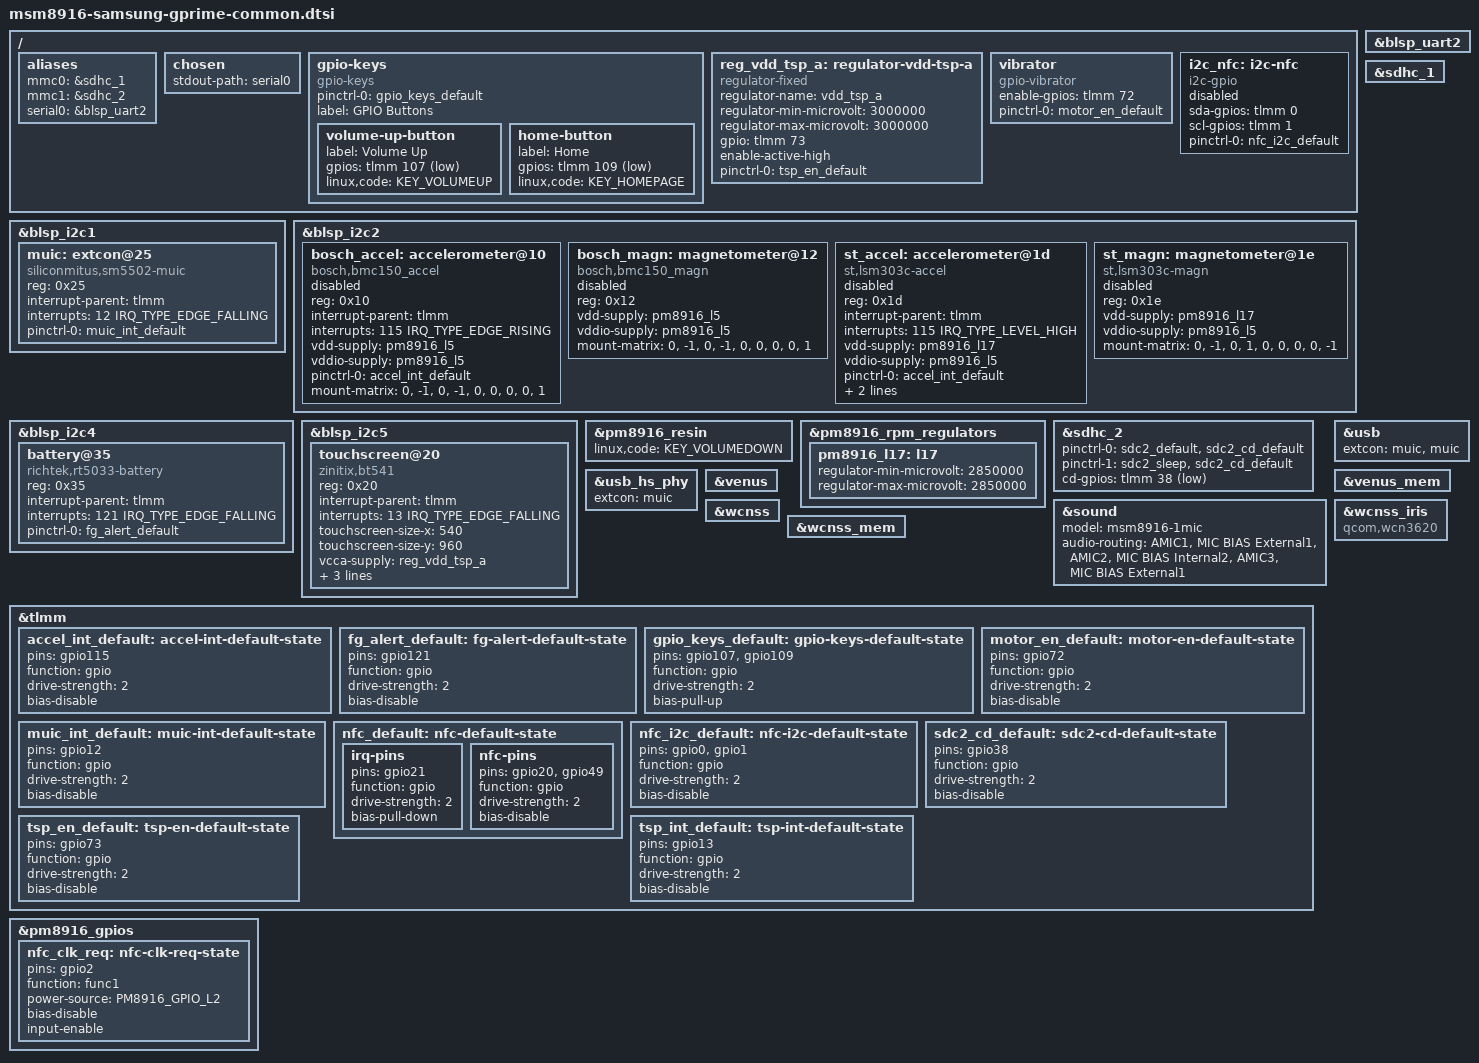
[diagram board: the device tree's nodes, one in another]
// SPDX-License-Identifier: GPL-2.0-only

#include "msm8916-pm8916.dtsi"
#include "msm8916-modem-qdsp6.dtsi"

#include <dt-bindings/gpio/gpio.h>
#include <dt-bindings/input/input.h>
#include <dt-bindings/interrupt-controller/irq.h>
#include <dt-bindings/pinctrl/qcom,pmic-gpio.h>

/ {
	aliases {
		mmc0 = &sdhc_1; /* eMMC */
		mmc1 = &sdhc_2; /* SD card */
		serial0 = &blsp_uart2;
	};

	chosen {
		stdout-path = "serial0";
	};

	gpio-keys {
		compatible = "gpio-keys";

		pinctrl-0 = <&gpio_keys_default>;
		pinctrl-names = "default";

		label = "GPIO Buttons";

		volume-up-button {
			label = "Volume Up";
			gpios = <&tlmm 107 GPIO_ACTIVE_LOW>;
			linux,code = <KEY_VOLUMEUP>;
		};

		home-button {
			label = "Home";
			gpios = <&tlmm 109 GPIO_ACTIVE_LOW>;
			linux,code = <KEY_HOMEPAGE>;
		};
	};

	reg_vdd_tsp_a: regulator-vdd-tsp-a {
		compatible = "regulator-fixed";
		regulator-name = "vdd_tsp_a";
		regulator-min-microvolt = <3000000>;
		regulator-max-microvolt = <3000000>;

		gpio = <&tlmm 73 GPIO_ACTIVE_HIGH>;
		enable-active-high;

		pinctrl-0 = <&tsp_en_default>;
		pinctrl-names = "default";
	};

	vibrator {
		compatible = "gpio-vibrator";
		enable-gpios = <&tlmm 72 GPIO_ACTIVE_HIGH>;

		pinctrl-0 = <&motor_en_default>;
		pinctrl-names = "default";
	};

	i2c_nfc: i2c-nfc {
		compatible = "i2c-gpio";
		sda-gpios = <&tlmm 0 (GPIO_ACTIVE_HIGH|GPIO_OPEN_DRAIN)>;
		scl-gpios = <&tlmm 1 (GPIO_ACTIVE_HIGH|GPIO_OPEN_DRAIN)>;

		pinctrl-0 = <&nfc_i2c_default>;
		pinctrl-names = "default";

		#address-cells = <1>;
		#size-cells = <0>;

		/* Used for NFC on some variants */
		status = "disabled";
	};
};

&blsp_i2c1 {
	status = "okay";

	muic: extcon@25 {
		compatible = "siliconmitus,sm5502-muic";
		reg = <0x25>;
		interrupt-parent = <&tlmm>;
		interrupts = <12 IRQ_TYPE_EDGE_FALLING>;
		pinctrl-0 = <&muic_int_default>;
		pinctrl-names = "default";
	};
};

&blsp_i2c2 {
	/* Available sensors vary depending on model variant */
	status = "okay";

	bosch_accel: accelerometer@10 {
		compatible = "bosch,bmc150_accel";
		reg = <0x10>;
		interrupt-parent = <&tlmm>;
		interrupts = <115 IRQ_TYPE_EDGE_RISING>;

		vdd-supply = <&pm8916_l5>;
		vddio-supply = <&pm8916_l5>;

		pinctrl-0 = <&accel_int_default>;
		pinctrl-names = "default";

		mount-matrix = "0", "-1", "0",
			      "-1",  "0", "0",
			       "0",  "0", "1";

		status = "disabled";
	};

	bosch_magn: magnetometer@12 {
		compatible = "bosch,bmc150_magn";
		reg = <0x12>;

		vdd-supply = <&pm8916_l5>;
		vddio-supply = <&pm8916_l5>;

		mount-matrix = "0", "-1", "0",
			      "-1",  "0", "0",
			       "0",  "0", "1";

		status = "disabled";
	};

	st_accel: accelerometer@1d {
		compatible = "st,lsm303c-accel";
		reg = <0x1d>;
		interrupt-parent = <&tlmm>;
		interrupts = <115 IRQ_TYPE_LEVEL_HIGH>;
		interrupt-names = "INT1";

		vdd-supply = <&pm8916_l17>;
		vddio-supply = <&pm8916_l5>;

		pinctrl-0 = <&accel_int_default>;
		pinctrl-names = "default";

		st,drdy-int-pin = <1>;
		mount-matrix = "0", "-1",  "0",
			       "1",  "0",  "0",
			       "0",  "0", "-1";

		status = "disabled";
	};

	st_magn: magnetometer@1e {
		compatible = "st,lsm303c-magn";
		reg = <0x1e>;

		vdd-supply = <&pm8916_l17>;
		vddio-supply = <&pm8916_l5>;

		mount-matrix = "0", "-1",  "0",
			       "1",  "0",  "0",
			       "0",  "0", "-1";

		status = "disabled";
	};
};

&blsp_i2c4 {
	status = "okay";

	battery@35 {
		compatible = "richtek,rt5033-battery";
		reg = <0x35>;

		interrupt-parent = <&tlmm>;
		interrupts = <121 IRQ_TYPE_EDGE_FALLING>;

		pinctrl-0 = <&fg_alert_default>;
		pinctrl-names = "default";
	};
};

&blsp_i2c5 {
	status = "okay";

	touchscreen@20 {
		compatible = "zinitix,bt541";
		reg = <0x20>;

		interrupt-parent = <&tlmm>;
		interrupts = <13 IRQ_TYPE_EDGE_FALLING>;

		touchscreen-size-x = <540>;
		touchscreen-size-y = <960>;

		vcca-supply = <&reg_vdd_tsp_a>;
		vdd-supply = <&pm8916_l6>;

		pinctrl-0 = <&tsp_int_default>;
		pinctrl-names = "default";

		linux,keycodes = <KEY_APPSELECT KEY_BACK>;
	};
};

&blsp_uart2 {
	status = "okay";
};

&pm8916_resin {
	linux,code = <KEY_VOLUMEDOWN>;
	status = "okay";
};

&pm8916_rpm_regulators {
	pm8916_l17: l17 {
		regulator-min-microvolt = <2850000>;
		regulator-max-microvolt = <2850000>;
	};
};

&sdhc_1 {
	status = "okay";
};

&sdhc_2 {
	pinctrl-0 = <&sdc2_default &sdc2_cd_default>;
	pinctrl-1 = <&sdc2_sleep &sdc2_cd_default>;
	pinctrl-names = "default", "sleep";

	cd-gpios = <&tlmm 38 GPIO_ACTIVE_LOW>;

	status = "okay";
};

&sound {
	model = "msm8916-1mic";
	audio-routing =
		"AMIC1", "MIC BIAS External1",
		"AMIC2", "MIC BIAS Internal2",
		"AMIC3", "MIC BIAS External1";
};

&usb {
	extcon = <&muic>, <&muic>;
	status = "okay";
};

&usb_hs_phy {
	extcon = <&muic>;
};

&venus {
	status = "okay";
};

&venus_mem {
	status = "okay";
};

&wcnss {
	status = "okay";
};

&wcnss_iris {
	compatible = "qcom,wcn3620";
};

&wcnss_mem {
	status = "okay";
};

&tlmm {
	accel_int_default: accel-int-default-state {
		pins = "gpio115";
		function = "gpio";
		drive-strength = <2>;
		bias-disable;
	};

	fg_alert_default: fg-alert-default-state {
		pins = "gpio121";
		function = "gpio";
		drive-strength = <2>;
		bias-disable;
	};

	gpio_keys_default: gpio-keys-default-state {
		pins = "gpio107", "gpio109";
		function = "gpio";
		drive-strength = <2>;
		bias-pull-up;
	};

	motor_en_default: motor-en-default-state {
		pins = "gpio72";
		function = "gpio";
		drive-strength = <2>;
		bias-disable;
	};

	muic_int_default: muic-int-default-state {
		pins = "gpio12";
		function = "gpio";
		drive-strength = <2>;
		bias-disable;
	};

	nfc_default: nfc-default-state {
		irq-pins {
			pins = "gpio21";
			function = "gpio";
			drive-strength = <2>;
			bias-pull-down;
		};

		nfc-pins {
			pins = "gpio20", "gpio49";
			function = "gpio";
			drive-strength = <2>;
			bias-disable;
		};
	};

	nfc_i2c_default: nfc-i2c-default-state {
		pins = "gpio0", "gpio1";
		function = "gpio";
		drive-strength = <2>;
		bias-disable;
	};

	sdc2_cd_default: sdc2-cd-default-state {
		pins = "gpio38";
		function = "gpio";
		drive-strength = <2>;
		bias-disable;
	};

	tsp_en_default: tsp-en-default-state {
		pins = "gpio73";
		function = "gpio";
		drive-strength = <2>;
		bias-disable;
	};

	tsp_int_default: tsp-int-default-state {
		pins = "gpio13";
		function = "gpio";
		drive-strength = <2>;
		bias-disable;
	};
};

&pm8916_gpios {
	nfc_clk_req: nfc-clk-req-state {
		pins = "gpio2";
		function = "func1";
		power-source = <PM8916_GPIO_L2>;
		bias-disable;
		input-enable;
	};
};
